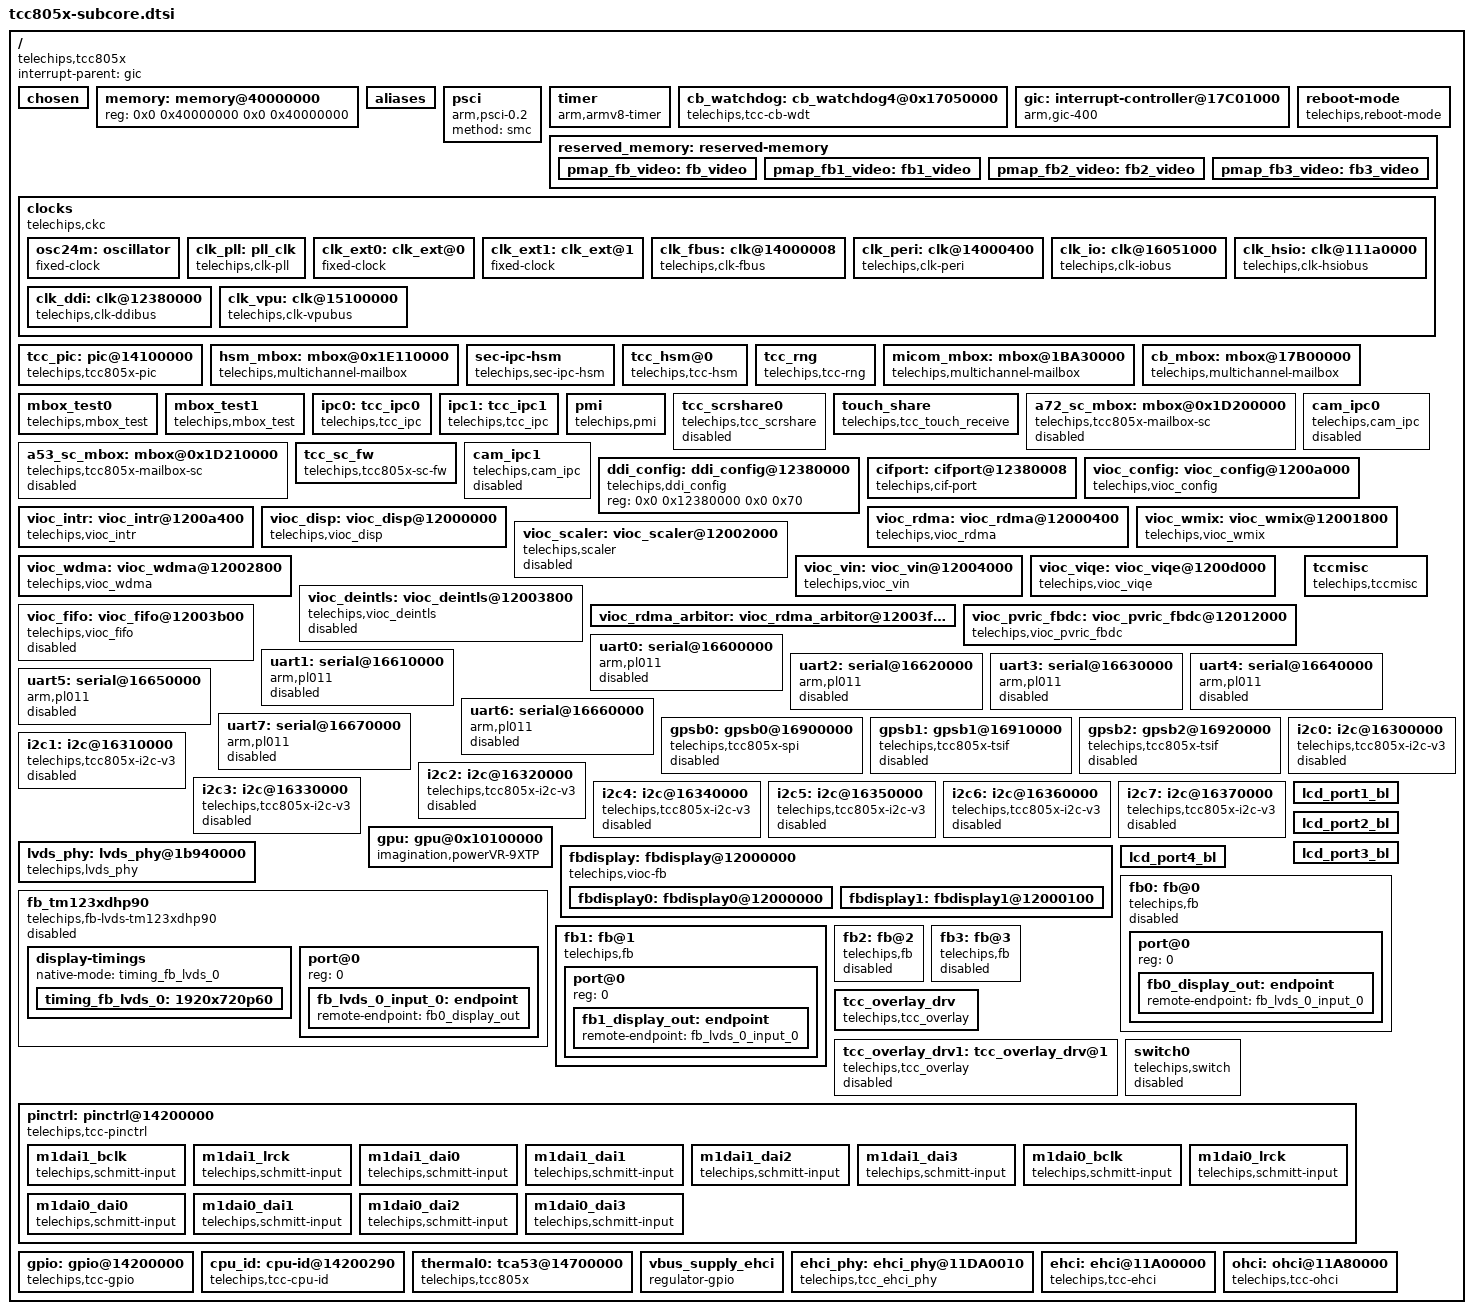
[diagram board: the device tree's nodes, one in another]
// SPDX-License-Identifier: (GPL-2.0-or-later OR MIT)
/*
 * Copyright (C) Telechips Inc.
 */

#include <dt-bindings/interrupt-controller/arm-gic.h>
#include <dt-bindings/clock/telechips,tcc805x-clks.h>
#include <dt-bindings/reset/telechips,tcc805x-reset.h>
#include <dt-bindings/display/tcc805x-vioc.h>
#include <dt-bindings/power/tcc805x,boot-mode.h>
#include <dt-bindings/gpio/gpio.h>
#include <dt-bindings/input/input.h>
#include <dt-bindings/mailbox/tcc805x_multi_mailbox/tcc_mbox_ch.h>
#include <dt-bindings/display/tcc805x-lvds.h>

/ {
	compatible = "telechips,tcc805x";
	interrupt-parent = <&gic>;
	#address-cells = <2>;
	#size-cells = <2>;

	chosen: chosen {
		bootargs = "vmalloc=480M cgroup_disable=memory console=ttyAMA0,115200n8 quiet";
		stdout-path = &uart4;
	};

	memory: memory@40000000 {
		#address-cells = <2>;
		#size-cells = <2>;
		device_type = "memory";
//		reg = <0x0 0x40000000 0x0 0x20000000>;
		reg = <0x0 0x40000000 0x0 0x40000000>;
	};

	aliases: aliases {
		serial0 = &uart0;
		serial1 = &uart1;
		serial2 = &uart2;
		serial3 = &uart3;
		serial4 = &uart4;
		serial5 = &uart5;
		serial6 = &uart6;
		serial7 = &uart7;
		i2c0 = &i2c0;
		i2c1 = &i2c1;
		i2c2 = &i2c2;
		i2c3 = &i2c3;
		i2c4 = &i2c4;
		i2c5 = &i2c5;
		i2c6 = &i2c6;
		i2c7 = &i2c7;
		switch0 = &switch0;
                fb0 = &fb0;
                fb1 = &fb1;
                fb2 = &fb2;
                fb3 = &fb3;
		tcc-overlay-drv1 = &tcc_overlay_drv1;
	};

	psci {
		compatible = "arm,psci-0.2";
		method = "smc";
	};

	timer {
		compatible = "arm,armv8-timer";
		interrupts = <GIC_PPI 13 (GIC_CPU_MASK_SIMPLE(4) | IRQ_TYPE_LEVEL_LOW)>,
			     <GIC_PPI 14 (GIC_CPU_MASK_SIMPLE(4) | IRQ_TYPE_LEVEL_LOW)>,
			     <GIC_PPI 11 (GIC_CPU_MASK_SIMPLE(4) | IRQ_TYPE_LEVEL_LOW)>,
			     <GIC_PPI 10 (GIC_CPU_MASK_SIMPLE(4) | IRQ_TYPE_LEVEL_LOW)>;
	};

	cb_watchdog: cb_watchdog4@0x17050000 {
		compatible = "telechips,tcc-cb-wdt";
		reg = <0x0 0x17050000 0x0 0x10>,
		      <0x0 0x14300010 0x0 0x10>,
		      <0x0 0x14300060 0x0 0x4>;
		interrupts = <GIC_SPI 34 IRQ_TYPE_LEVEL_HIGH>;
		clock-names = "clk_wdt", "clk_kick";
		clocks = <&clk_peri PERI_CB_WDT>, <&clk_peri PERI_TCT>;
		clock-frequency = <24000000>;

		kick-timer-id = /bits/ 8 <0x1>;
		pretimeout-sec = <5>;
		timeout-sec = <20>;
	};

	gic: interrupt-controller@17C01000 {
		compatible = "arm,gic-400";
		#interrupt-cells = <3>;
		#address-cells = <0>;
		interrupt-controller;
		reg = <0x0 0x17C01000 0x0 0x1000>,
		      <0x0 0x17C02000 0x0 0x2000>,
		      <0x0 0x17C04000 0x0 0x2000>,
		      <0x0 0x17C06000 0x0 0x2000>;
	};

	reboot-mode {
		compatible = "telechips,reboot-mode";
		mode-normal = <BOOT_NORMAL>;
		mode-bootloader = <BOOT_FASTBOOT>;
		mode-recovery = <BOOT_RECOVERY>;
		mode-ddrcheck = <BOOT_DDR_CHECK>;
		record-panic = <BOOT_PANIC>;
	};

	reserved_memory: reserved-memory {
		#address-cells = <2>;
		#size-cells = <2>;
		ranges;

		pmap_fb_video: fb_video {};
		pmap_fb1_video: fb1_video {};
		pmap_fb2_video: fb2_video {};
		pmap_fb3_video: fb3_video {};
	};

	clocks {
		compatible = "telechips,ckc";

		osc24m: oscillator {
			compatible = "fixed-clock";
			#clock-cells = <0>;
			clock-frequency = <24000000>;
			clock-output-names = "osc24m";
		};

		clk_pll: pll_clk {
			compatible = "telechips,clk-pll";
			#clock-cells = <1>;
			clocks = <&osc24m>;
			clock-output-names = "pll0", "pll1", "pll2", "pll3",
					     "pll4";
		};

		clk_ext0: clk_ext@0 {
			compatible = "fixed-clock";
			#clock-cells = <0>;
			clock-frequency = <24000000>;
			clock-output-names = "clk_ext0";
		};

		clk_ext1: clk_ext@1 {
			compatible = "fixed-clock";
			#clock-cells = <0>;
			clock-frequency = <24000000>;
			clock-output-names = "clk_ext1";
		};

		clk_fbus: clk@14000008 {
			compatible = "telechips,clk-fbus";
			#clock-cells = <1>;
			clock-indices =
				<FBUS_CPU0>, <FBUS_CPU1>, <FBUS_CBUS>, <FBUS_CMBUS>,
				<FBUS_HSIO>, <FBUS_SMU>, <FBUS_GPU>, <FBUS_DDI>,
				<FBUS_G2D>, <FBUS_IO>, <FBUS_HSM>, <FBUS_PCIe0>,
				<FBUS_PCIe1>, <FBUS_VBUS>, <FBUS_CODA>, <FBUS_CHEVCDEC>,
				<FBUS_BHEVCDEC>, <FBUS_CHEVCENC>, <FBUS_BHEVCENC>, <FBUS_MEM>,
				<FBUS_MEM_SUB>, <FBUS_MEM_PHY_USER>,
				<FBUS_MEM_PHY_PERI>;
			clock-output-names =
				"fbus_cpu0", "fbus_cpu1", "fbus_cbus", "fbus_cmbus",
				"fbus_hsio", "fbus_smu", "fbus_gpu", "fbus_ddi",
				"fbus_g2d", "fbus_io", "fbus_hsm", "fbus_pcie0",
				"fbus_pcie1", "fbus_vbus", "fbus_coda", "fbus_chevcdec",
				"fbus_bhevcdec", "fbus_chevcenc", "fbus_bhevcenc", "fbus_mem",
				"fbus_mem_sub", "fbus_mem_phy_user",
				"fbus_mem_phy_peri";
			telechips,clock-flags =
				<0>,    /* FBUS_CPU0 */
				<CLK_IGNORE_UNUSED>,    /* FBUS_CPU1 */
				<(CLK_SET_RATE_GATE | CLK_IGNORE_UNUSED)>,    /* FBUS_CBUS */
				<(CLK_SET_RATE_GATE | CLK_IGNORE_UNUSED)>,    /* FBUS_CMBUS */
				<(CLK_SET_RATE_GATE | CLK_IGNORE_UNUSED)>,    /* FBUS_HSIO */
				<(CLK_SET_RATE_GATE | CLK_IGNORE_UNUSED)>,    /* FBUS_SMU */
				<(CLK_SET_RATE_GATE | CLK_IGNORE_UNUSED)>,   /* FBUS_GPU */
				<(CLK_SET_RATE_GATE | CLK_IGNORE_UNUSED)>,    /* FBUS_DDI */
				<(CLK_SET_RATE_GATE | CLK_IGNORE_UNUSED)>,    /* FBUS_G2D */
				<(CLK_SET_RATE_GATE | CLK_IS_CRITICAL)>,    /* FBUS_IO */
				<(CLK_SET_RATE_GATE | CLK_IGNORE_UNUSED)>,    /* FBUS_HSM */
				<(CLK_SET_RATE_GATE | CLK_IGNORE_UNUSED)>,    /* FBUS_PCIe0 */
				<(CLK_SET_RATE_GATE | CLK_IGNORE_UNUSED)>,    /* FBUS_PCIe1 */
				<(CLK_SET_RATE_GATE | CLK_IGNORE_UNUSED)>,    /* FBUS_VBUS */
				<(CLK_SET_RATE_GATE | CLK_IGNORE_UNUSED)>,    /* FBUS_CODA */
				<(CLK_SET_RATE_GATE | CLK_IGNORE_UNUSED)>,    /* FBUS_CHEVCDEC */
				<(CLK_SET_RATE_GATE | CLK_IGNORE_UNUSED)>,    /* FBUS_BHEVCDEC */
				<(CLK_SET_RATE_GATE | CLK_IGNORE_UNUSED)>,    /* FBUS_CHEVCENC */
				<(CLK_SET_RATE_GATE | CLK_IGNORE_UNUSED)>,    /* FBUS_BHEVCENC */
				<(CLK_SET_RATE_GATE | CLK_IGNORE_UNUSED)>,    /* FBUS_MEM */
				<(CLK_SET_RATE_GATE | CLK_IGNORE_UNUSED)>,    /* FBUS_MEM_SUB */
				<(CLK_SET_RATE_GATE | CLK_IGNORE_UNUSED)>,    /* FBUS_MEM_PHY_USER */
				<(CLK_SET_RATE_GATE | CLK_IGNORE_UNUSED)>;    /* FBUS_MEM_PHY_PERI */
		};

		clk_peri: clk@14000400 {
			compatible = "telechips,clk-peri";
			#clock-cells = <1>;
			clock-indices =
				<PERI_TCX>, <PERI_TCT>, <PERI_TCZ>,
				<PERI_LCDTIMER>, <PERI_LCD0>, <PERI_LCD1>,
				<PERI_LCD2>, <PERI_CPUINTERFACE0>,
				<PERI_CPUINTERFACE1>, <PERI_LCD3>, <PERI_GMAC>,
				<PERI_GMAC_PTP>, <PERI_PCIE0_AUX>,
				<PERI_PCIE0_REF_EXT>, <PERI_PCIE0_PHY_CR_CLK>,
				<PERI_PCIE1_AUX>, <PERI_PCIE1_REF_EXT>,
				<PERI_PCIE1_PHY_CR_CLK>, <PERI_RMT>, <PERI_GPSB3>,
				<PERI_SDMMC1>, <PERI_SDMMC2>, <PERI_CEC1_CORE>,
				<PERI_MDAI0>, <PERI_MFLT0_DAI>, <PERI_MSPDIF0>,
				<PERI_SRCH0_CORE>, <PERI_SRCH0_FILTER>,
				<PERI_SRCH0_SPDIF>, <PERI_PDM>, <PERI_CEC1_SFR>,
				<PERI_TSADC>, <PERI_I2C0>, <PERI_I2C1>, <PERI_I2C2>,
				<PERI_I2C3>, <PERI_UART0>, <PERI_UART1>,
				<PERI_UART2>, <PERI_UART3>, <PERI_MDAI1>,
				<PERI_MFLT1_DAI>, <PERI_MSPDIF1>, <PERI_MDAI2>,
				<PERI_GPSB0>, <PERI_GPSB1>, <PERI_GPSB2>,
				<PERI_GPSBMS0>, <PERI_GPSBMS1>, <PERI_GPSBMS2>,
				<PERI_UART4>, <PERI_AUX0_INPUT>,
				<PERI_AUX1_INPUT>, <PERI_MFLT2_DAI>,
				<PERI_AUX0_OUTPUT>, <PERI_AUX1_OUTPUT>,
				<PERI_MSPDIF2>, <PERI_IC_TC>, <PERI_SRCH1_CORE>,
				<PERI_SRCH1_FILTER>, <PERI_SRCH1_SPDIF>,
				<PERI_SRCH2_CORE>, <PERI_SRCH2_FILTER>,
				<PERI_SRCH2_SPDIF>, <PERI_SRCH3_CORE>,
				<PERI_SRCH3_FILTER>, <PERI_SRCH3_SPDIF>,
				<PERI_UART5>, <PERI_UART6>, <PERI_UART7>,
				<PERI_UART8>, <PERI_MDAI3>, <PERI_MFLT3_DAI>,
				<PERI_MSPDIF3>, <PERI_TSRX0>, <PERI_TSRX1>,
				<PERI_TSRX2>, <PERI_TSRX3>, <PERI_TSRX4>,
				<PERI_TSRX5>, <PERI_TSRX6>, <PERI_TSRX7>,
				<PERI_TSRX8>, <PERI_CB_WDT>, <PERI_OUT0>,
				<PERI_OUT1>, <PERI_OUT2>, <PERI_OUT3>, <PERI_OUT4>,
				<PERI_OUT5>, <PERI_HSMB>;

				clock-output-names =
				"peri_tcx", "peri_tct", "peri_tcz",
				"peri_lcdtimer", "peri_lcd0", "peri_lcd1",
				"peri_lcd2", "peri_cpuinterface0",
				"peri_cpuinterface1", "peri_lcd3", "peri_gmac",
				"peri_gmac_ptp", "peri_pcie0_aux",
				"peri_pcie0_ref_ext", "peri_pcie0_phy_cr_clk",
				"peri_pcie1_aux", "peri_pcie1_ref_ext",
				"peri_pcie1_phy_cr_clk", "peri_rmt", "peri_gpsb3",
				"peri_sdmmc1", "peri_sdmmc2", "peri_cec1_core",
				"peri_mdai0", "peri_mflt0_dai", "peri_mspdif0",
				"peri_srch0_core", "peri_srch0_filter",
				"peri_srch0_spdif", "peri_pdm", "peri_cec1_sfr",
				"peri_tsadc", "peri_i2c0", "peri_i2c1", "peri_i2c2",
				"peri_i2c3", "peri_uart0", "peri_uart1",
				"peri_uart2", "peri_uart3", "peri_mdai1",
				"peri_mflt1_dai", "peri_mspdif1", "peri_mdai2",
				"peri_gpsb0", "peri_gpsb1", "peri_gpsb2",
				"peri_gpsbms0", "peri_gpsbms1", "peri_gpsbms2",
				"peri_uart4", "peri_aux0_input",
				"peri_aux1_input", "peri_mflt2_dai",
				"peri_aux0_output", "peri_aux1_output",
				"peri_mspdif2", "peri_ic_tc", "peri_srch1_core",
				"peri_srch1_filter", "peri_srch1_spdif",
				"peri_srch2_core", "peri_srch2_filter",
				"peri_srch2_spdif", "peri_srch3_core",
				"peri_srch3_filter", "peri_srch3_spdif",
				"peri_uart5", "peri_uart6", "peri_uart7",
				"peri_uart8", "peri_mdai3", "peri_mflt3_dai",
				"peri_mspdif3", "peri_tsrx0", "peri_tsrx1",
				"peri_tsrx2", "peri_tsrx3", "peri_tsrx4",
				"peri_tsrx5", "peri_tsrx6", "peri_tsrx7",
				"peri_tsrx8", "peri_cb_wdt", "peri_out0",
				"peri_out1", "peri_out2", "peri_out3", "peri_out4",
				"peri_out5", "peri_hsmb";
			telechips,clock-flags =
				<CLK_IGNORE_UNUSED>,    /* PERI_TCX */
				<CLK_IGNORE_UNUSED>,    /* PERI_TCT */
				<CLK_IGNORE_UNUSED>,    /* PERI_TCZ */
				<CLK_IGNORE_UNUSED>,    /* PERI_LCDTIMER */
				<CLK_IGNORE_UNUSED>,    /* PERI_LCD0 */
				<CLK_IGNORE_UNUSED>,    /* PERI_LCD1 */
				<CLK_IGNORE_UNUSED>,    /* PERI_LCD2 */
				<CLK_IGNORE_UNUSED>,    /* PERI_CPUINTERFACE0 */
				<CLK_IGNORE_UNUSED>,    /* PERI_CPUINTERFACE1 */
				<CLK_IGNORE_UNUSED>,    /* PERI_LCD3 */
				<CLK_IGNORE_UNUSED>,    /* PERI_GMAC */
				<CLK_IGNORE_UNUSED>,    /* PERI_GMAC_PTP */
				<CLK_IGNORE_UNUSED>,    /* PERI_PCIE0_AUX */
				<CLK_IGNORE_UNUSED>,    /* PERI_PCIE0_REF_EXT */
				<CLK_IGNORE_UNUSED>,    /* PERI_PCIE0_PHY_CR_CLK */
				<CLK_IGNORE_UNUSED>,    /* PERI_PCIE1_AUX */
				<CLK_IGNORE_UNUSED>,    /* PERI_PCIE1_REF_EXT */
				<CLK_IGNORE_UNUSED>,    /* PERI_PCIE1_PHY_CR_CLK */
				<CLK_IGNORE_UNUSED>,    /* PERI_RMT */
				<CLK_IGNORE_UNUSED>,    /* PERI_GPSB3 */
				<CLK_IGNORE_UNUSED>,    /* PERI_SDMMC1 */
				<CLK_IGNORE_UNUSED>,    /* PERI_SDMMC2 */
				<CLK_IGNORE_UNUSED>,    /* PERI_CEC1_CORE */
				<CLK_IGNORE_UNUSED>,    /* PERI_MDAI0 */
				<CLK_IGNORE_UNUSED>,    /* PERI_MFLT0_DAI */
				<CLK_IGNORE_UNUSED>,    /* PERI_MSPDIF0 */
				<CLK_IGNORE_UNUSED>,    /* PERI_SRCH0_CORE */
				<CLK_IGNORE_UNUSED>,    /* PERI_SRCH0_FILTER */
				<CLK_IGNORE_UNUSED>,    /* PERI_SRCH0_SPDIF */
				<CLK_IGNORE_UNUSED>,    /* PERI_PDM */
				<CLK_IGNORE_UNUSED>,    /* PERI_CEC1_SFR */
				<CLK_IGNORE_UNUSED>,    /* PERI_TSADC */
				<CLK_IGNORE_UNUSED>,    /* PERI_I2C0 */
				<CLK_IGNORE_UNUSED>,    /* PERI_I2C1 */
				<CLK_IGNORE_UNUSED>,    /* PERI_I2C2 */
				<CLK_IGNORE_UNUSED>,    /* PERI_I2C3 */
				<CLK_IGNORE_UNUSED>,    /* PERI_UART0 */
				<CLK_IGNORE_UNUSED>,    /* PERI_UART1 */
				<CLK_IGNORE_UNUSED>,    /* PERI_UART2 */
				<CLK_IGNORE_UNUSED>,    /* PERI_UART3 */
				<CLK_IGNORE_UNUSED>,    /* PERI_MDAI1 */
				<CLK_IGNORE_UNUSED>,    /* PERI_MFLT1_DAI */
				<CLK_IGNORE_UNUSED>,    /* PERI_MSPDIF1 */
				<CLK_IGNORE_UNUSED>,    /* PERI_MDAI2 */
				<CLK_IGNORE_UNUSED>,    /* PERI_GPSB0 */
				<CLK_IGNORE_UNUSED>,    /* PERI_GPSB1 */
				<CLK_IGNORE_UNUSED>,    /* PERI_GPSB2 */
				<CLK_IGNORE_UNUSED>,    /* PERI_GPSBMS0 */
				<CLK_IGNORE_UNUSED>,    /* PERI_GPSBMS1 */
				<CLK_IGNORE_UNUSED>,    /* PERI_GPSBMS2 */
				<CLK_IGNORE_UNUSED>,    /* PERI_UART4 */
				<CLK_IGNORE_UNUSED>,    /* PERI_AUX0_INPUT */
				<CLK_IGNORE_UNUSED>,    /* PERI_AUX1_INPUT */
				<CLK_IGNORE_UNUSED>,    /* PERI_MFLT2_DAI */
				<CLK_IGNORE_UNUSED>,    /* PERI_AUX0_OUTPUT */
				<CLK_IGNORE_UNUSED>,    /* PERI_AUX1_OUTPUT */
				<CLK_IGNORE_UNUSED>,    /* PERI_MSPDIF2 */
				<CLK_IGNORE_UNUSED>,    /* PERI_IC_TC */
				<CLK_IGNORE_UNUSED>,    /* PERI_SRCH1_CORE */
				<CLK_IGNORE_UNUSED>,    /* PERI_SRCH1_FILTER */
				<CLK_IGNORE_UNUSED>,    /* PERI_SRCH1_SPDIF */
				<CLK_IGNORE_UNUSED>,    /* PERI_SRCH2_CORE */
				<CLK_IGNORE_UNUSED>,    /* PERI_SRCH2_FILTER */
				<CLK_IGNORE_UNUSED>,    /* PERI_SRCH2_SPDIF */
				<CLK_IGNORE_UNUSED>,    /* PERI_SRCH3_CORE */
				<CLK_IGNORE_UNUSED>,    /* PERI_SRCH3_FILTER */
				<CLK_IGNORE_UNUSED>,    /* PERI_SRCH3_SPDIF */
				<CLK_IGNORE_UNUSED>,    /* PERI_UART5 */
				<CLK_IGNORE_UNUSED>,    /* PERI_UART6 */
				<CLK_IGNORE_UNUSED>,    /* PERI_UART7 */
				<CLK_IGNORE_UNUSED>,    /* PERI_UART8 */
				<CLK_IGNORE_UNUSED>,    /* PERI_MDAI3 */
				<CLK_IGNORE_UNUSED>,    /* PERI_MFLT3_DAI */
				<CLK_IGNORE_UNUSED>,    /* PERI_MSPDIF3 */
				<CLK_IGNORE_UNUSED>,    /* PERI_TSRX0 */
				<CLK_IGNORE_UNUSED>,    /* PERI_TSRX1 */
				<CLK_IGNORE_UNUSED>,    /* PERI_TSRX2 */
				<CLK_IGNORE_UNUSED>,    /* PERI_TSRX3 */
				<CLK_IGNORE_UNUSED>,    /* PERI_TSRX4 */
				<CLK_IGNORE_UNUSED>,    /* PERI_TSRX5 */
				<CLK_IGNORE_UNUSED>,    /* PERI_TSRX6 */
				<CLK_IGNORE_UNUSED>,    /* PERI_TSRX7 */
				<CLK_IGNORE_UNUSED>,    /* PERI_TSRX8 */
				<CLK_IGNORE_UNUSED>,    /* PERI_CB_WDT */
				<CLK_IGNORE_UNUSED>,    /* PERI_OUT0 */
				<CLK_IGNORE_UNUSED>,    /* PERI_OUT1 */
				<CLK_IGNORE_UNUSED>,    /* PERI_OUT2 */
				<CLK_IGNORE_UNUSED>,    /* PERI_OUT3 */
				<CLK_IGNORE_UNUSED>,    /* PERI_OUT4 */
				<CLK_IGNORE_UNUSED>,    /* PERI_OUT5 */
				<CLK_IGNORE_UNUSED>;    /* PERI_HSMB */
		};

		clk_io: clk@16051000 {
			compatible = "telechips,clk-iobus";
			#clock-cells = <1>;
			clocks = <&clk_fbus FBUS_IO>;
			clock-indices =
				<IOBUS_IC_TC>, <IOBUS_GPSB6>, <IOBUS_PL080>,
                                <IOBUS_ASRC>, <IOBUS_DMA0>, <IOBUS_DMA1>,
                                <IOBUS_DMA2>, <IOBUS_DMA>, <IOBUS_PWM>,
                                <IOBUS_I2C_S2>, <IOBUS_REMOCON>, <IOBUS_PRT>,
                                <IOBUS_ADMA0>, <IOBUS_DAI0>, <IOBUS_SPDIF0>,
                                <IOBUS_AUDIO0>, <IOBUS_ADMA3>, <IOBUS_DAI3>,
                                <IOBUS_SPDIF3>, <IOBUS_AUDIO3>, <IOBUS_I2C_M0>,
                                <IOBUS_I2C_M1>, <IOBUS_I2C_M2>, <IOBUS_I2C_M3>,
                                <IOBUS_I2C_S0>, <IOBUS_I2C_S1>, <IOBUS_I2C0>,
                                <IOBUS_I2C1>, <IOBUS_GPSB_2>, <IOBUS_GPSB0>,
                                <IOBUS_GPSB1>, <IOBUS_GPSB2>, <IOBUS_GPSB3>,
                                <IOBUS_GPSB4>, <IOBUS_GPSB5>, <IOBUS_GPSB>,
                                <IOBUS_I2C_S3>, <IOBUS_I2C_M4>, <IOBUS_I2C_M5>,
                                <IOBUS_I2C_M6>, <IOBUS_I2C_M7>, <IOBUS_UART0>,
                                <IOBUS_UART1>, <IOBUS_UART2>, <IOBUS_UART3>,
                                <IOBUS_UART4>, <IOBUS_UART5>, <IOBUS_UART6>,
                                <IOBUS_UART7>, <IOBUS_UART8>, <IOBUS_SMARTCARD4>,
                                <IOBUS_UDMA0>, <IOBUS_UDMA1>, <IOBUS_UDMA2>,
                                <IOBUS_UDMA3>, <IOBUS_UART_SMARTCARD0>,
                                <IOBUS_UART_SMARTCARD1>, <IOBUS_UDMA4>, <IOBUS_UDMA5>,
                                <IOBUS_UDMA6>, <IOBUS_UDMA7>, <IOBUS_UDMA8>,
                                <IOBUS_ADMA1>, <IOBUS_DAI1>, <IOBUS_SPDIF1>,
                                <IOBUS_AUDIO1>, <IOBUS_ADMA2>, <IOBUS_DAI2>,
                                <IOBUS_SPDIF2>, <IOBUS_AUDIO2>, <IOBUS_ADMA4>,
                                <IOBUS_DAI4>, <IOBUS_SPDIF4>, <IOBUS_AUDIO4>,
                                <IOBUS_ADMA5>, <IOBUS_DAI5>, <IOBUS_SPDIF5>,
                                <IOBUS_AUDIO5>, <IOBUS_ADMA6>, <IOBUS_DAI6>,
                                <IOBUS_SPDIF6>, <IOBUS_AUDIO6>, <IOBUS_ADMA7>,
                                <IOBUS_DAI7>, <IOBUS_AUDIO7>, <IOBUS_GDMA1>,
                                <IOBUS_SDMMC1>, <IOBUS_SDMMC2>, <IOBUS_SDMMC>,
                                <IOBUS_SMC>, <IOBUS_NFC>, <IOBUS_EDICFG>,
                                <IOBUS_EDI>, <IOBUS_RTC>;
			clock-output-names =
				"iobus_ic_tc", "iobus_gpsb6", "iobus_pl080",
                                "iobus_asrc", "iobus_dma0", "iobus_dma1",
                                "iobus_dma2", "iobus_dma", "iobus_pwm",
                                "iobus_i2c_s2", "iobus_remocon", "iobus_prt",
                                "iobus_adma0", "iobus_dai0", "iobus_spdif0",
                                "iobus_audio0", "iobus_adma3", "iobus_dai3",
                                "iobus_spdif3", "iobus_audio3", "iobus_i2c_m0",
                                "iobus_i2c_m1", "iobus_i2c_m2", "iobus_i2c_m3",
                                "iobus_i2c_s0", "iobus_i2c_s1", "iobus_i2c0",
                                "iobus_i2c1", "iobus_gpsb_2", "iobus_gpsb0",
                                "iobus_gpsb1", "iobus_gpsb2", "iobus_gpsb3",
                                "iobus_gpsb4", "iobus_gpsb5", "iobus_gpsb",
                                "iobus_i2c_s3", "iobus_i2c_m4", "iobus_i2c_m5",
                                "iobus_i2c_m6", "iobus_i2c_m7", "iobus_uart0",
                                "iobus_uart1", "iobus_uart2", "iobus_uart3",
                                "iobus_uart4", "iobus_uart5", "iobus_uart6",
                                "iobus_uart7", "iobus_uart8", "iobus_smartcard4",
                                "iobus_udma0", "iobus_udma1", "iobus_udma2",
                                "iobus_udma3", "iobus_uart_smartcard0",
                                "iobus_uart_smartcard1", "iobus_udma4", "iobus_udma5",
                                "iobus_udma6", "iobus_udma7", "iobus_udma8",
                                "iobus_adma1", "iobus_dai1", "iobus_spdif1",
                                "iobus_audio1", "iobus_adma2", "iobus_dai2",
                                "iobus_spdif2", "iobus_audio2", "iobus_adma4",
                                "iobus_dai4", "iobus_spdif4", "iobus_audio4",
                                "iobus_adma5", "iobus_dai5", "iobus_spdif5",
                                "iobus_audio5", "iobus_adma6", "iobus_dai6",
                                "iobus_spdif6", "iobus_audio6", "iobus_adma7",
                                "iobus_dai7", "iobus_audio7", "iobus_gdma1",
                                "iobus_sdmmc1", "iobus_sdmmc2", "iobus_sdmmc",
                                "iobus_smc", "iobus_nfc", "iobus_edicfg",
                                "iobus_edi", "iobus_rtc";
			telechips,clock-flags =
				<CLK_IGNORE_UNUSED>,    /* IOBUS_IC_TC */
                                <CLK_IGNORE_UNUSED>,    /* IOBUS_GPSB6 */
                                <CLK_IGNORE_UNUSED>,    /* IOBUS_PL080 */
                                <CLK_IGNORE_UNUSED>,    /* IOBUS_ASRC */
                                <CLK_IGNORE_UNUSED>,    /* IOBUS_DMA0 */
                                <CLK_IGNORE_UNUSED>,    /* IOBUS_DMA1 */
                                <CLK_IGNORE_UNUSED>,    /* IOBUS_DMA2 */
                                <CLK_IGNORE_UNUSED>,    /* IOBUS_DMA */
                                <CLK_IGNORE_UNUSED>,    /* IOBUS_PWM */
                                <CLK_IGNORE_UNUSED>,    /* IOBUS_I2C_S2 */
                                <CLK_IGNORE_UNUSED>,    /* IOBUS_REMOCON */
                                <CLK_IGNORE_UNUSED>,    /* IOBUS_PRT */
                                <CLK_IGNORE_UNUSED>,    /* IOBUS_ADMA0 */
                                <CLK_IGNORE_UNUSED>,    /* IOBUS_DAI0 */
                                <CLK_IGNORE_UNUSED>,    /* IOBUS_SPDIF0 */
                                <CLK_IGNORE_UNUSED>,    /* IOBUS_AUDIO0 */
                                <CLK_IGNORE_UNUSED>,    /* IOBUS_ADMA3 */
                                <CLK_IGNORE_UNUSED>,    /* IOBUS_DAI3 */
                                <CLK_IGNORE_UNUSED>,    /* IOBUS_SPDIF3 */
                                <CLK_IGNORE_UNUSED>,    /* IOBUS_AUDIO3 */
                                <CLK_IGNORE_UNUSED>,    /* IOBUS_I2C_M0 */
                                <CLK_IGNORE_UNUSED>,    /* IOBUS_I2C_M1 */
                                <CLK_IGNORE_UNUSED>,    /* IOBUS_I2C_M2 */
                                <CLK_IGNORE_UNUSED>,    /* IOBUS_I2C_M3 */
                                <CLK_IGNORE_UNUSED>,    /* IOBUS_I2C_S0 */
                                <CLK_IGNORE_UNUSED>,    /* IOBUS_I2C_S1 */
                                <CLK_IGNORE_UNUSED>,    /* IOBUS_I2C0 */
                                <CLK_IGNORE_UNUSED>,    /* IOBUS_I2C1 */
                                <CLK_IGNORE_UNUSED>,    /* IOBUS_GPSB_2 */
                                <CLK_IGNORE_UNUSED>,    /* IOBUS_GPSB0 */
                                <CLK_IGNORE_UNUSED>,    /* IOBUS_GPSB1 */
                                <CLK_IGNORE_UNUSED>,    /* IOBUS_GPSB2 */
                                <CLK_IGNORE_UNUSED>,    /* IOBUS_GPSB3 */
                                <CLK_IGNORE_UNUSED>,    /* IOBUS_GPSB4 */
                                <CLK_IGNORE_UNUSED>,    /* IOBUS_GPSB5 */
                                <CLK_IGNORE_UNUSED>,    /* IOBUS_GPSB */
                                <CLK_IGNORE_UNUSED>,    /* IOBUS_I2C_S3 */
                                <CLK_IGNORE_UNUSED>,    /* IOBUS_I2C_M4 */
                                <CLK_IGNORE_UNUSED>,    /* IOBUS_I2C_M5 */
                                <CLK_IGNORE_UNUSED>,    /* IOBUS_I2C_M6 */
                                <CLK_IGNORE_UNUSED>,    /* IOBUS_I2C_M7 */
                                <CLK_IGNORE_UNUSED>,    /* IOBUS_UART0 */
                                <CLK_IGNORE_UNUSED>,    /* IOBUS_UART1 */
                                <CLK_IGNORE_UNUSED>,    /* IOBUS_UART2 */
                                <CLK_IGNORE_UNUSED>,    /* IOBUS_UART3 */
                                <CLK_IGNORE_UNUSED>,    /* IOBUS_UART4 */
                                <CLK_IGNORE_UNUSED>,    /* IOBUS_UART5 */
                                <CLK_IGNORE_UNUSED>,    /* IOBUS_UART6 */
                                <CLK_IGNORE_UNUSED>,    /* IOBUS_UART7 */
                                <CLK_IGNORE_UNUSED>,    /* IOBUS_UART8 */
                                <CLK_IGNORE_UNUSED>,    /* IOBUS_SMARTCARD4 */
                                <CLK_IGNORE_UNUSED>,    /* IOBUS_UDMA0 */
                                <CLK_IGNORE_UNUSED>,    /* IOBUS_UDMA1 */
                                <CLK_IGNORE_UNUSED>,    /* IOBUS_UDMA2 */
                                <CLK_IGNORE_UNUSED>,    /* IOBUS_UDMA3 */
                                <CLK_IGNORE_UNUSED>,    /* IOBUS_UART_SMARTCARD0 */
                                <CLK_IGNORE_UNUSED>,    /* IOBUS_UART_SMARTCARD1 */
                                <CLK_IGNORE_UNUSED>,    /* IOBUS_UDMA4 */
                                <CLK_IGNORE_UNUSED>,    /* IOBUS_UDMA5 */
				<CLK_IGNORE_UNUSED>,    /* IOBUS_UDMA6 */
                                <CLK_IGNORE_UNUSED>,    /* IOBUS_UDMA7 */
                                <CLK_IGNORE_UNUSED>,    /* IOBUS_UDMA8 */
                                <CLK_IGNORE_UNUSED>,    /* IOBUS_ADMA1 */
                                <CLK_IGNORE_UNUSED>,    /* IOBUS_DAI1 */
                                <CLK_IGNORE_UNUSED>,    /* IOBUS_SPDIF1 */
                                <CLK_IGNORE_UNUSED>,    /* IOBUS_AUDIO1 */
                                <CLK_IGNORE_UNUSED>,    /* IOBUS_ADMA2 */
                                <CLK_IGNORE_UNUSED>,    /* IOBUS_DAI2 */
                                <CLK_IGNORE_UNUSED>,    /* IOBUS_SPDIF2 */
                                <CLK_IGNORE_UNUSED>,    /* IOBUS_AUDIO2 */
                                <CLK_IGNORE_UNUSED>,    /* IOBUS_ADMA4 */
                                <CLK_IGNORE_UNUSED>,    /* IOBUS_DAI4 */
                                <CLK_IGNORE_UNUSED>,    /* IOBUS_SPDIF4 */
                                <CLK_IGNORE_UNUSED>,    /* IOBUS_AUDIO4 */
                                <CLK_IGNORE_UNUSED>,    /* IOBUS_ADMA5 */
                                <CLK_IGNORE_UNUSED>,    /* IOBUS_DAI5 */
                                <CLK_IGNORE_UNUSED>,    /* IOBUS_SPDIF5 */
                                <CLK_IGNORE_UNUSED>,    /* IOBUS_AUDIO5 */
                                <CLK_IGNORE_UNUSED>,    /* IOBUS_ADMA6 */
                                <CLK_IGNORE_UNUSED>,    /* IOBUS_DAI6 */
                                <CLK_IGNORE_UNUSED>,    /* IOBUS_SPDIF6 */
                                <CLK_IGNORE_UNUSED>,    /* IOBUS_AUDIO6 */
                                <CLK_IGNORE_UNUSED>,    /* IOBUS_ADMA7 */
                                <CLK_IGNORE_UNUSED>,    /* IOBUS_DAI7 */
                                <CLK_IGNORE_UNUSED>,    /* IOBUS_AUDIO7 */
                                <CLK_IGNORE_UNUSED>,    /* IOBUS_GDMA1 */
                                <CLK_IGNORE_UNUSED>,    /* IOBUS_SDMMC1 */
                                <CLK_IGNORE_UNUSED>,    /* IOBUS_SDMMC2 */
                                <CLK_IGNORE_UNUSED>,    /* IOBUS_SDMMC */
                                <CLK_IGNORE_UNUSED>,    /* IOBUS_SMC */
                                <CLK_IGNORE_UNUSED>,    /* IOBUS_NFC */
                                <CLK_IGNORE_UNUSED>,    /* IOBUS_EDICFG */
                                <CLK_IGNORE_UNUSED>,    /* IOBUS_EDI */
                                <CLK_IGNORE_UNUSED>;    /* IOBUS_RTC */
		};

		clk_hsio: clk@111a0000 {
			compatible = "telechips,clk-hsiobus";
			#clock-cells = <1>;
			clocks = <&clk_fbus FBUS_HSIO>;
			clock-indices =
				<HSIOBUS_USB30>, <HSIOBUS_GMAC>,
                                <HSIOBUS_USB20H>, <HSIOBUS_CIPHER>,
                                <HSIOBUS_DWC_OTG>, <HSIOBUS_SECURE_WRAP>,
                                <HSIOBUS_TRNG>;
			clock-output-names =
				"hsiobus_usb30", "hsiobus_gmac",
                                "hsiobus_usb20h", "hsiobus_cipher",
                                "hsiobus_dwc_otg", "hsiobus_secure_wrap",
                                "hsiobus_trng";
			telechips,clock-flags =
				<CLK_IGNORE_UNUSED>,    /* HSIOBUS_USB30 */
                                <CLK_IGNORE_UNUSED>,    /* HSIOBUS_GMAC */
                                <CLK_IGNORE_UNUSED>,    /* HSIOBUS_USB20H */
                                <CLK_IGNORE_UNUSED>,    /* HSIOBUS_CIPHER */
                                <CLK_IGNORE_UNUSED>,    /* HSIOBUS_DWC_OTG */
                                <CLK_IGNORE_UNUSED>,    /* HSIOBUS_SECURE_WRAP */
                                <CLK_IGNORE_UNUSED>;    /* HSIOBUS_TRNG */
		};

		clk_ddi: clk@12380000 {
			compatible = "telechips,clk-ddibus";
			#clock-cells = <1>;
			clocks = <&clk_fbus FBUS_DDI>;
			clock-indices =
				<DDIBUS_VIOC>, <DDIBUS_HDMI>, <DDIBUS_MIPI>,
				<DDIBUS_LVDS>;
			clock-output-names =
				"ddibus_vioc", "ddibus_hdmi", "ddibus_mipi",
				"ddibus_lvds";
			telechips,clock-flags =
				<CLK_IGNORE_UNUSED>,	/* DDIBUS_VIOC */
				<CLK_IGNORE_UNUSED>,	/* DDIBUS_HDMI */
				<CLK_IGNORE_UNUSED>,	/* DDIBUS_MIPI */
				<CLK_IGNORE_UNUSED>;	/* DDIBUS_LVDS */
		};

		clk_vpu: clk@15100000 {
			compatible = "telechips,clk-vpubus";
			#clock-cells = <1>;
			clocks = <&clk_fbus FBUS_VBUS>;
			clock-indices =
				<VIDEOBUS_JPEG>, <VIDEOBUS_CODA_BUS>,
				<VIDEOBUS_CODA_CORE>, <VIDEOBUS_HEVC_BUS>,
				<VIDEOBUS_HEVC_CORE>, <VIDEOBUS_HEVC_ENCODER>;
			clock-output-names =
				"videobus_jpeg", "videobus_coda_bus",
				"videobus_coda_core", "videobus_hevc_bus",
				"videobus_hevc_core", "videobus_hevc_encoder";
			telechips,clock-flags =
				<CLK_IGNORE_UNUSED>,	/* VIDEOBUS_JPEG */
				<CLK_IGNORE_UNUSED>,	/* VIDEOBUS_CODA_BUS */
				<CLK_IGNORE_UNUSED>,	/* VIDEOBUS_CODA_CORE */
				<CLK_IGNORE_UNUSED>,	/* VIDEOBUS_HEVC_BUS */
				<CLK_IGNORE_UNUSED>,	/* VIDEOBUS_HEVC_CORE */
				<CLK_IGNORE_UNUSED>;	/* VIDEOBUS_HEVC_ENCODER */
		};
	};

	tcc_pic: pic@14100000 {
		compatible = "telechips,tcc805x-pic";
		reg = <0x0 0x141000E0 0x0 0x0018>,  /* pol_0_base */
		      <0x0 0x14600100 0x0 0x0024>,  /* pol_1_base */
		      <0x0 0x14800040 0x0 0x003C>,  /* cmb_cm4_base */
		      <0x0 0x14900040 0x0 0x003C>,  /* strgb_cm4_base */
		      <0x0 0x0 0x0 0x0>;            /* ca7_irqo_en_base */
		demarcation = <192>;
		max_irq = <480>;
	};

	/* A53 <-> HSM core */
	hsm_mbox: mbox@0x1E110000 {
		compatible = "telechips,multichannel-mailbox";
		reg = <0x0 0x1E110000 0x0 0x100>;
		interrupts = <GIC_SPI 308 IRQ_TYPE_LEVEL_HIGH>,
					<GIC_SPI 336 IRQ_TYPE_LEVEL_HIGH>;
		#mbox-cells = <1>;
		max-channel = <TCC_HSM_MBOX0_MAX>;
	};

	sec-ipc-hsm {
		compatible = "telechips,sec-ipc-hsm";
		mbox-names = "sec-ipc-hsm";
		mboxes = <&hsm_mbox TCC_HSM_MBOX1>;
		mbox-id = TCC_MBOX_HSM_ID;
	};

	tcc_hsm@0 {
		compatible = "telechips,tcc-hsm";
		status = "okay";
	};

	tcc_rng {
		compatible = "telechips,tcc-rng";
		status = "okay";
	};

	/* A53 <-> R5 */
	micom_mbox: mbox@1BA30000 {
		compatible = "telechips,multichannel-mailbox";
		reg = <0x0 0x1BA30000 0x0 0x100>;
		interrupts = <GIC_SPI 444 IRQ_TYPE_LEVEL_HIGH>,
			<GIC_SPI 445 IRQ_TYPE_LEVEL_HIGH>;
		#mbox-cells = <1>;
		max-channel = <TCC_MICOM_MBOX1_MAX>;
	};

	/* A53 <-> A72 */
	cb_mbox: mbox@17B00000 {
		compatible = "telechips,multichannel-mailbox";
		reg = <0x0 0x17B00000 0x0 0x100>;
		interrupts = <GIC_SPI 365 IRQ_TYPE_LEVEL_HIGH>,
			<GIC_SPI 366 IRQ_TYPE_LEVEL_HIGH>;
		#mbox-cells = <1>;
		max-channel = <TCC_CB_MBOX_MAX>;
	};

	/* micom_mbox test */
	mbox_test0: mbox_test0 {
		compatible = "telechips,mbox_test";
		device-name = "micom_mbox_test";
		mbox-names ="mbox_test";
		mboxes = <&micom_mbox TCC_MICOM_MBOX1_TEST>;
		mbox-id = TCC_MBOX_TEST_ID;
	};

	/* cb_mbox test */
	mbox_test1: mbox_test1 {
	    compatible = "telechips,mbox_test";
	    device-name = "cb_mbox_test";
	    mbox-names ="mbox_test";
	    mboxes = <&cb_mbox TCC_CB_MBOX_TEST>;
	    mbox-id = TCC_MBOX_TEST_ID;
	};

	/* ipc for r5(micom) */
	ipc0: tcc_ipc0 {
		compatible = "telechips,tcc_ipc";
		device-name = "tcc_ipc_micom";
		mbox-names ="micom-ipc";
		mboxes = <&micom_mbox TCC_MICOM_MBOX1_IPC>;
		mbox-id = TCC_MBOX_IPC_ID;
	  };

	/* ipc for A72 */
	ipc1: tcc_ipc1 {
		compatible = "telechips,tcc_ipc";
		device-name = "tcc_ipc_ap";
		mbox-names ="ap-ipc";
		mboxes = <&cb_mbox TCC_CB_MBOX_IPC>;
		mbox-id = TCC_MBOX_IPC_ID;
	};

	/* power management interface driver */
	pmi {
		compatible = "telechips,pmi";
		mboxes = <&micom_mbox TCC_MICOM_MBOX1_POWER>;
		mbox-id = TCC_MBOX_POWER_ID;
	};

	/* tcc_scrshare for Sub */
	tcc_scrshare0: tcc_scrshare0 {
		compatible = "telechips,tcc_scrshare";
		device-name ="tcc_scrshare_sub";
		mbox-names ="sub-scrshare";
		mboxes = <&cb_mbox TCC_CB_MBOX_SCRSHARE>;
		mbox-id = TCC_MBOX_SCRSHARE_ID;
		overlay_driver_names = "/dev/overlay1";
		status = "disabled";
    };

	/* touch receive driver */
	touch_share {
	    compatible = "telechips,tcc_touch_receive";
	    mbox-names ="tr-mbox";
	    mboxes = <&cb_mbox TCC_CB_MBOX_TCHSHARE>;
	    mbox-id = TCC_MBOX_TCHSHARE_ID;
	    xmax = <1920>;
	    ymax = <720>;
	};

	/* A72 <-> SC */
	a72_sc_mbox: mbox@0x1D200000 {
		status = "disabled";
		compatible = "telechips,tcc805x-mailbox-sc";
		reg = <0x0 0x1D200000 0x0 0x80>;
		interrupts = <GIC_SPI 319 IRQ_TYPE_LEVEL_HIGH>,
		             <GIC_SPI 329 IRQ_TYPE_LEVEL_HIGH>;
		#mbox-cells = <1>;
	};

	/* A53 <-> SC */
	a53_sc_mbox: mbox@0x1D210000 {
		status = "disabled";
		compatible = "telechips,tcc805x-mailbox-sc";
		reg = <0x0 0x1D210000 0x0 0x80>;
		interrupts = <GIC_SPI 320 IRQ_TYPE_LEVEL_HIGH>,
		             <GIC_SPI 330 IRQ_TYPE_LEVEL_HIGH>;
		#mbox-cells = <1>;
	};

	tcc_sc_fw: tcc_sc_fw {
		status = "disabled";
		compatible = "telechips,tcc805x-sc-fw";
	};

	/* cam_ipc for A53 */
	cam_ipc0: cam_ipc0 {
		compatible = "telechips,cam_ipc";
		device-name ="cam_ipc_ap";
		mbox-names ="cam-ipc-ap";
		mboxes = <&cb_mbox TCC_CB_MBOX_CAMIPC>;
		mbox-id = TCC_MBOX_CAMIPC_ID;
		status = "disabled";
	};

	/* cam_ipc for trvc */
	cam_ipc1: cam_ipc1 {
		compatible = "telechips,cam_ipc";
		device-name ="cam_ipc_micom";
		mbox-names ="cam-ipc-micom";
		mboxes = <&micom_mbox TCC_MICOM_MBOX1_CAMIPC>;
		mbox-id = TCC_MBOX_CAMIPC_ID;
		status = "disabled";
	};

	/*
	 * Display Bus Block
	 */
	ddi_config: ddi_config@12380000 {
		compatible = "telechips,ddi_config";
		reg = <0x0 0x12380000 0x0 0x70>;
	};

	cifport: cifport@12380008 {
		compatible = "telechips,cif-port";
		reg = <0x0 0x12380008 0x0 0x4>;
		statue = "okay";
	};

	vioc_config: vioc_config@1200a000 {
		compatible = "telechips,vioc_config";
		reg =  <0x0 0x1200a000 0x0 0x1000>,
			/* VIOC_REMAP */
		       <0x0 0x12046000 0x0 0x1000>;
	};

	vioc_intr: vioc_intr@1200a400 {
		compatible = "telechips,vioc_intr";
		reg =  <0x0 0x1200a400 0x0 0x100>,
			/* VIOC_REMAP */
		       <0x0 0x12046400 0x0 0x100>;
		interrupts = <GIC_SPI VIOC0_IRQI IRQ_TYPE_LEVEL_HIGH>;
	};

	vioc_disp: vioc_disp@12000000 {
		compatible = "telechips,vioc_disp";
		reg =  <0x0 0x12000000 0x0 0x100
			0x0 0x12000100 0x0 0x100
			0x0 0x12000200 0x0 0x100
			0x0 0x12000300 0x0 0x100>,
			/* VIOC_REMAP */
		       <0x0 0x12000000 0x0 0x100
			0x0 0x12001000 0x0 0x100
			0x0 0x12002000 0x0 0x100
			0x0 0x12003000 0x0 0x100>;
		interrupts = <GIC_SPI VIOC0_IRQI IRQ_TYPE_LEVEL_HIGH>, <GIC_SPI VIOC0_IRQI IRQ_TYPE_LEVEL_HIGH>, <GIC_SPI VIOC0_IRQI IRQ_TYPE_LEVEL_HIGH>, <GIC_SPI VIOC0_IRQI IRQ_TYPE_LEVEL_HIGH>;
		clocks = <&clk_ddi DDIBUS_VIOC>, <&clk_peri PERI_LCD0>, <&clk_peri PERI_LCD1>, <&clk_peri PERI_LCD2>, <&clk_peri PERI_LCD3>;
		clock-names = "ddi-clk", "disp0-clk", "disp1-clk", "disp2-clk", "disp3-clk";
	};

	vioc_rdma: vioc_rdma@12000400 {
		compatible = "telechips,vioc_rdma";
		reg =  <0x0 0x12000400 0x0 0x100
			0x0 0x12000500 0x0 0x100
			0x0 0x12000600 0x0 0x100
			0x0 0x12000700 0x0 0x100
			0x0 0x12000800 0x0 0x100
			0x0 0x12000900 0x0 0x100
			0x0 0x12000a00 0x0 0x100
			0x0 0x12000b00 0x0 0x100
			0x0 0x12000c00 0x0 0x100
			0x0 0x12000d00 0x0 0x100
			0x0 0x12000e00 0x0 0x100
			0x0 0x12000f00 0x0 0x100
			0x0 0x12001000 0x0 0x100
			0x0 0x12001100 0x0 0x100
			0x0 0x12001200 0x0 0x100
			0x0 0x12001300 0x0 0x100
			0x0 0x12001400 0x0 0x100
			0x0 0x12001500 0x0 0x100>,
			/* VIOC_REMAP */
		       <0x0 0x12004000 0x0 0x100
			0x0 0x12005000 0x0 0x100
			0x0 0x12006000 0x0 0x100
			0x0 0x12007000 0x0 0x100
			0x0 0x12008000 0x0 0x100
			0x0 0x12009000 0x0 0x100
			0x0 0x1200a000 0x0 0x100
			0x0 0x1200b000 0x0 0x100
			0x0 0x1200c000 0x0 0x100
			0x0 0x1200d000 0x0 0x100
			0x0 0x1200e000 0x0 0x100
			0x0 0x1200f000 0x0 0x100
			0x0 0x12010000 0x0 0x100
			0x0 0x12011000 0x0 0x100
			0x0 0x12012000 0x0 0x100
			0x0 0x12013000 0x0 0x100
			0x0 0x12014000 0x0 0x100
			0x0 0x12015000 0x0 0x100>;
		interrupts = <GIC_SPI VIOC0_IRQI IRQ_TYPE_LEVEL_HIGH>,
			     <GIC_SPI VIOC0_IRQI IRQ_TYPE_LEVEL_HIGH>,
			     <GIC_SPI VIOC0_IRQI IRQ_TYPE_LEVEL_HIGH>,
			     <GIC_SPI VIOC0_IRQI IRQ_TYPE_LEVEL_HIGH>,
			     <GIC_SPI VIOC0_IRQI IRQ_TYPE_LEVEL_HIGH>,
			     <GIC_SPI VIOC0_IRQI IRQ_TYPE_LEVEL_HIGH>,
			     <GIC_SPI VIOC0_IRQI IRQ_TYPE_LEVEL_HIGH>,
			     <GIC_SPI VIOC0_IRQI IRQ_TYPE_LEVEL_HIGH>,
			     <GIC_SPI VIOC0_IRQI IRQ_TYPE_LEVEL_HIGH>,
			     <GIC_SPI VIOC0_IRQI IRQ_TYPE_LEVEL_HIGH>,
			     <GIC_SPI VIOC0_IRQI IRQ_TYPE_LEVEL_HIGH>,
			     <GIC_SPI VIOC0_IRQI IRQ_TYPE_LEVEL_HIGH>,
			     <GIC_SPI VIOC0_IRQI IRQ_TYPE_LEVEL_HIGH>,
			     <GIC_SPI VIOC0_IRQI IRQ_TYPE_LEVEL_HIGH>,
			     <GIC_SPI VIOC0_IRQI IRQ_TYPE_LEVEL_HIGH>,
			     <GIC_SPI VIOC0_IRQI IRQ_TYPE_LEVEL_HIGH>,
			     <GIC_SPI VIOC0_IRQI IRQ_TYPE_LEVEL_HIGH>,
			     <GIC_SPI VIOC0_IRQI IRQ_TYPE_LEVEL_HIGH>;
	};

	vioc_wmix: vioc_wmix@12001800 {
		compatible = "telechips,vioc_wmix";
		reg =  <0x0 0x12001800 0x0 0x100
			0x0 0x12001900 0x0 0x100
			0x0 0x12001a00 0x0 0x100
			0x0 0x12001b00 0x0 0x100
			0x0 0x12001c00 0x0 0x100
			0x0 0x12001d00 0x0 0x100
			0x0 0x12001e00 0x0 0x100>,
			/* VIOC_REMAP */
		       <0x0 0x12018000 0x0 0x100
			0x0 0x12019000 0x0 0x100
			0x0 0x1201a000 0x0 0x100
			0x0 0x1201b000 0x0 0x100
			0x0 0x1201c000 0x0 0x100
			0x0 0x1201d000 0x0 0x100
			0x0 0x1201e000 0x0 0x100>;
		interrupts = <GIC_SPI VIOC0_IRQI IRQ_TYPE_LEVEL_HIGH>,
			     <GIC_SPI VIOC0_IRQI IRQ_TYPE_LEVEL_HIGH>,
			     <GIC_SPI VIOC0_IRQI IRQ_TYPE_LEVEL_HIGH>,
			     <GIC_SPI VIOC0_IRQI IRQ_TYPE_LEVEL_HIGH>,
			     <GIC_SPI VIOC0_IRQI IRQ_TYPE_LEVEL_HIGH>,
			     <GIC_SPI VIOC0_IRQI IRQ_TYPE_LEVEL_HIGH>,
			     <GIC_SPI VIOC0_IRQI IRQ_TYPE_LEVEL_HIGH>;
	};

	vioc_scaler: vioc_scaler@12002000 {
		compatible = "telechips,scaler";
		reg =  <0x0 0x12002000 0x0 0x100
			0x0 0x12002100 0x0 0x100
			0x0 0x12002200 0x0 0x100
			0x0 0x12002300 0x0 0x100
			0x0 0x12002400 0x0 0x100
			0x0 0x12002500 0x0 0x100
			0x0 0x12002600 0x0 0x100
			0x0 0x12002700 0x0 0x100>,
			/* VIOC_REMAP */
		       <0x0 0x12020000 0x0 0x100
			0x0 0x12021000 0x0 0x100
			0x0 0x12022000 0x0 0x100
			0x0 0x12023000 0x0 0x100
			0x0 0x12024000 0x0 0x100
			0x0 0x12025000 0x0 0x100
			0x0 0x12026000 0x0 0x100
			0x0 0x12027000 0x0 0x100>;
		status = "disabled";
	};

	vioc_wdma: vioc_wdma@12002800 {
		compatible = "telechips,vioc_wdma";
		reg =  <0x0 0x12002800 0x0 0x100 0x0 0x12002900 0x0 0x100
			0x0 0x12002a00 0x0 0x100 0x0 0x12002b00 0x0 0x100
			0x0 0x12002c00 0x0 0x100 0x0 0x12002d00 0x0 0x100
			0x0 0x12002e00 0x0 0x100 0x0 0x12002f00 0x0 0x100
			0x0 0x12003000 0x0 0x100 0x0 0x12014000 0x0 0x100
			0x0 0x12014100 0x0 0x100 0x0 0x12014200 0x0 0x100
			0x0 0x12014300 0x0 0x100 0x0 0x12014400 0x0 0x100>,
			/* VIOC_REMAP */
		       <0x0 0x12028000 0x0 0x100 0x0 0x12029000 0x0 0x100
			0x0 0x1202a000 0x0 0x100 0x0 0x1202b000 0x0 0x100
			0x0 0x1202c000 0x0 0x100 0x0 0x1202d000 0x0 0x100
			0x0 0x1202e000 0x0 0x100 0x0 0x1202f000 0x0 0x100
			0x0 0x12030000 0x0 0x100 0x0 0x12052000 0x0 0x100
			0x0 0x12053000 0x0 0x100 0x0 0x12054000 0x0 0x100
			0x0 0x12059000 0x0 0x100 0x0 0x1205a000 0x0 0x100>;
		interrupts = <GIC_SPI VIOC0_IRQI IRQ_TYPE_LEVEL_HIGH>,
			     <GIC_SPI VIOC0_IRQI IRQ_TYPE_LEVEL_HIGH>,
			     <GIC_SPI VIOC0_IRQI IRQ_TYPE_LEVEL_HIGH>,
			     <GIC_SPI VIOC0_IRQI IRQ_TYPE_LEVEL_HIGH>,
			     <GIC_SPI VIOC0_IRQI IRQ_TYPE_LEVEL_HIGH>,
			     <GIC_SPI VIOC0_IRQI IRQ_TYPE_LEVEL_HIGH>,
			     <GIC_SPI VIOC0_IRQI IRQ_TYPE_LEVEL_HIGH>,
			     <GIC_SPI VIOC0_IRQI IRQ_TYPE_LEVEL_HIGH>,
			     <GIC_SPI VIOC0_IRQI IRQ_TYPE_LEVEL_HIGH>,
			     <GIC_SPI VIOC0_IRQI IRQ_TYPE_LEVEL_HIGH>,
			     <GIC_SPI VIOC0_IRQI IRQ_TYPE_LEVEL_HIGH>,
			     <GIC_SPI VIOC0_IRQI IRQ_TYPE_LEVEL_HIGH>,
			     <GIC_SPI VIOC0_IRQI IRQ_TYPE_LEVEL_HIGH>,
			     <GIC_SPI VIOC0_IRQI IRQ_TYPE_LEVEL_HIGH>;
	};

	vioc_vin: vioc_vin@12004000 {
		compatible = "telechips,vioc_vin";
		reg =     <0x0 0x12004000 0x0 0x400 0x0 0x12004400 0x0 0x600
			   0x0 0x12005000 0x0 0x400 0x0 0x12005400 0x0 0x600
			   0x0 0x12006000 0x0 0x400 0x0 0x12006400 0x0 0x600
			   0x0 0x12007000 0x0 0x400 0x0 0x12007400 0x0 0x600
			   0x0 0x12018000 0x0 0x400 0x0 0x12018400 0x0 0x600
			   0x0 0x12019000 0x0 0x400 0x0 0x12019400 0x0 0x600
			   0x0 0x1201a000 0x0 0x400 0x0 0x1201a400 0x0 0x600
			   0x0 0x1201b000 0x0 0x400 0x0 0x1201b400 0x0 0x600>,
			/* VIOC_REMAP */
			  <0x0 0x12040000 0x0 0x400 0x0 0x12040400 0x0 0x600
			   0x0 0x12041000 0x0 0x400 0x0 0x12041400 0x0 0x600
			   0x0 0x12042000 0x0 0x400 0x0 0x12042400 0x0 0x600
			   0x0 0x12043000 0x0 0x400 0x0 0x12043400 0x0 0x600
			   0x0 0x12055000 0x0 0x400 0x0 0x12055400 0x0 0x600
			   0x0 0x12056000 0x0 0x400 0x0 0x12056400 0x0 0x600
			   0x0 0x12057000 0x0 0x400 0x0 0x12057400 0x0 0x600
			   0x0 0x12058000 0x0 0x400 0x0 0x12058400 0x0 0x600>;
		interrupts = <GIC_SPI VIOC0_IRQI IRQ_TYPE_LEVEL_HIGH>,
			     <GIC_SPI VIOC0_IRQI IRQ_TYPE_LEVEL_HIGH>,
			     <GIC_SPI VIOC0_IRQI IRQ_TYPE_LEVEL_HIGH>,
			     <GIC_SPI VIOC0_IRQI IRQ_TYPE_LEVEL_HIGH>,
			     <GIC_SPI VIOC0_IRQI IRQ_TYPE_LEVEL_HIGH>,
			     <GIC_SPI VIOC0_IRQI IRQ_TYPE_LEVEL_HIGH>,
			     <GIC_SPI VIOC0_IRQI IRQ_TYPE_LEVEL_HIGH>,
			     <GIC_SPI VIOC0_IRQI IRQ_TYPE_LEVEL_HIGH>,
			     <GIC_SPI VIOC0_IRQI IRQ_TYPE_LEVEL_HIGH>,
			     <GIC_SPI VIOC0_IRQI IRQ_TYPE_LEVEL_HIGH>,
			     <GIC_SPI VIOC0_IRQI IRQ_TYPE_LEVEL_HIGH>,
			     <GIC_SPI VIOC0_IRQI IRQ_TYPE_LEVEL_HIGH>,
			     <GIC_SPI VIOC0_IRQI IRQ_TYPE_LEVEL_HIGH>,
			     <GIC_SPI VIOC0_IRQI IRQ_TYPE_LEVEL_HIGH>,
			     <GIC_SPI VIOC0_IRQI IRQ_TYPE_LEVEL_HIGH>,
			     <GIC_SPI VIOC0_IRQI IRQ_TYPE_LEVEL_HIGH>;
	};

	vioc_viqe: vioc_viqe@1200d000 {
		compatible = "telechips,vioc_viqe";
		reg =  <0x0 0x1200d000 0x0 0x1000
			0x0 0x12010000 0x0 0x1000>,
			/* VIOC_REMAP */
		       <0x0 0x1204b000 0x0 0x1000
			0x0 0x1204e000 0x0 0x1000>;
	};

	vioc_deintls:vioc_deintls@12003800 {
		compatible = "telechips,vioc_deintls";
		reg =  <0x0 0x12003800 0x0 0x100>,
			/* VIOC_REMAP */
		       <0x0 0x12038000 0x0 0x100>;
		status = "disabled";
	};

	vioc_fifo:vioc_fifo@12003b00 {
		compatible = "telechips,vioc_fifo";
		reg =  <0x0 0x12003b00 0x0 0x100>,
			/* VIOC_REMAP */
		       <0x0 0x1203b000 0x0 0x100>;
		status = "disabled";
	};

	vioc_rdma_arbitor:vioc_rdma_arbitor@12003f00 {
		reg =  <0x0 0x12003f00 0x0 0x20
			0x0 0x12003f20 0x0 0x20
			0x0 0x12003f40 0x0 0x20
			0x0 0x12003f60 0x0 0x20>,
			/* VIOC_REMAP */
		       <0x0 0x1203f000 0x0 0x20
			0x0 0x1203f020 0x0 0x20
			0x0 0x1203f040 0x0 0x20
			0x0 0x1203f060 0x0 0x20>;
		arbitor_num = <4>;
	};

	vioc_pvric_fbdc:vioc_pvric_fbdc@12012000{
		compatible = "telechips,vioc_pvric_fbdc";
		status = "okay";
		reg =  <0x0 0x12012000 0x0 0x100
			0x0 0x12013000 0x0 0x100>,
			/* VIOC_REMAP */
		       <0x0 0x12050000 0x0 0x100
			0x0 0x12051000 0x0 0x100>;
	};

	tccmisc:tccmisc {
		/* Only use kernel-5.4 or up */
		compatible = "telechips,tccmisc";
		status = "okay";
	};

	uart0: serial@16600000 {
		compatible = "arm,pl011", "arm,primecell";
		reg = <0x0 0x16600000 0x0 0x1000>;
		config-reg = <0x16689000 0x8 9>;
		arm,primecell-periphid = <0x001feff7>;
                sc-firmware = <&tcc_sc_fw>;
		interrupts = <GIC_SPI 88 IRQ_TYPE_LEVEL_HIGH>;
		clocks = <&clk_peri PERI_UART0>, <&clk_io IOBUS_UART0>;
		clock-names = "uartclk", "apb_pclk";
		assigned-clocks = <&clk_peri PERI_UART0>;
		assigned-clock-rates = <48000000>;
		pinctrl-names = "default";
		status = "disabled";
	};

	uart1: serial@16610000 {
		compatible = "arm,pl011", "arm,primecell";
		reg = <0x0 0x16610000 0x0 0x1000>;
		config-reg = <0x16689000 0x8 9>;
		arm,primecell-periphid = <0x001feff7>;
		sc-firmware = <&tcc_sc_fw>;
		interrupts = <GIC_SPI 89 IRQ_TYPE_LEVEL_HIGH>;
		clocks = <&clk_peri PERI_UART1>, <&clk_io IOBUS_UART1>;
		clock-names = "uartclk", "apb_pclk";
		assigned-clocks = <&clk_peri PERI_UART1>;
		assigned-clock-rates = <48000000>;
		pinctrl-names = "default";
		status = "disabled";
	};

	uart2: serial@16620000 {
		compatible = "arm,pl011", "arm,primecell";
		reg = <0x0 0x16620000 0x0 0x1000>;
		config-reg = <0x16689000 0x8 9>;
		arm,primecell-periphid = <0x001feff7>;
		sc-firmware = <&tcc_sc_fw>;
		interrupts = <GIC_SPI 90 IRQ_TYPE_LEVEL_HIGH>;
		clocks = <&clk_peri PERI_UART2>, <&clk_io IOBUS_UART2>;
		clock-names = "uartclk", "apb_pclk";
		assigned-clocks = <&clk_peri PERI_UART2>;
		assigned-clock-rates = <48000000>;
		pinctrl-names = "default";
		status = "disabled";
	};

	uart3: serial@16630000 {
		compatible = "arm,pl011", "arm,primecell";
		reg = <0x0 0x16630000 0x0 0x1000>;
		config-reg = <0x16689000 0x8 9>;
		arm,primecell-periphid = <0x001feff7>;
		sc-firmware = <&tcc_sc_fw>;
		interrupts = <GIC_SPI 91 IRQ_TYPE_LEVEL_HIGH>;
		clocks = <&clk_peri PERI_UART3>, <&clk_io IOBUS_UART3>;
		clock-names = "uartclk", "apb_pclk";
		assigned-clocks = <&clk_peri PERI_UART3>;
		assigned-clock-rates = <48000000>;
		pinctrl-names = "default";
		status = "disabled";
	};

	uart4: serial@16640000 {
		compatible = "arm,pl011", "arm,primecell";
		reg = <0x0 0x16640000 0x0 0x1000>;
		config-reg = <0x16689000 0x8 9>;
		arm,primecell-periphid = <0x001feff7>;
		sc-firmware = <&tcc_sc_fw>;
		interrupts = <GIC_SPI 69 IRQ_TYPE_LEVEL_HIGH>;
		clocks = <&clk_peri PERI_UART4>, <&clk_io IOBUS_UART4>;
		clock-names = "uartclk", "apb_pclk";
		pinctrl-names = "default";
		status = "disabled";
	};

	uart5: serial@16650000 {
		compatible = "arm,pl011", "arm,primecell";
		reg = <0x0 0x16650000 0x0 0x1000>;
		config-reg = <0x16689000 0x8 9>;
		arm,primecell-periphid = <0x001feff7>;
		sc-firmware = <&tcc_sc_fw>;
		interrupts = <GIC_SPI 111 IRQ_TYPE_LEVEL_HIGH>;
		clocks = <&clk_peri PERI_UART5>, <&clk_io IOBUS_UART5>;
		clock-names = "uartclk", "apb_pclk";
		assigned-clocks = <&clk_peri PERI_UART5>;
		assigned-clock-rates = <48000000>;
		pinctrl-names = "default";
		status = "disabled";
	};

	uart6: serial@16660000 {
		compatible = "arm,pl011", "arm,primecell";
		reg = <0x0 0x16660000 0x0 0x1000>;
		config-reg = <0x16689000 0x8 9>;
		arm,primecell-periphid = <0x001feff7>;
		sc-firmware = <&tcc_sc_fw>;
		interrupts = <GIC_SPI 112 IRQ_TYPE_LEVEL_HIGH>;
		clocks = <&clk_peri PERI_UART6>, <&clk_io IOBUS_UART6>;
		clock-names = "uartclk", "apb_pclk";
		assigned-clocks = <&clk_peri PERI_UART6>;
		assigned-clock-rates = <48000000>;
		pinctrl-names = "default";
		status = "disabled";
	};

	uart7: serial@16670000 {
		compatible = "arm,pl011", "arm,primecell";
		reg = <0x0 0x16670000 0x0 0x1000>;
		config-reg = <0x16689000 0x8 9>;
		arm,primecell-periphid = <0x001feff7>;
		sc-firmware = <&tcc_sc_fw>;
		interrupts = <GIC_SPI 113 IRQ_TYPE_LEVEL_HIGH>;
		clocks = <&clk_peri PERI_UART7>, <&clk_io IOBUS_UART7>;
		clock-names = "uartclk", "apb_pclk";
		assigned-clocks = <&clk_peri PERI_UART7>;
		assigned-clock-rates = <48000000>;
		pinctrl-names = "default";
		status = "disabled";
	};

	gpsb0: gpsb0@16900000 {
		compatible = "telechips,tcc805x-spi";
		reg = <0x0 0x16900000 0x0 0x38>, /* base address */
		      <0x0 0x16960000 0x0 0x20>, /* Port Configuration register */
		      <0x0 0x16980000 0x0 0x20>; /* GPSB_0_AC */
		interrupts = <GIC_SPI 55 IRQ_TYPE_LEVEL_HIGH>;
		clocks = <&clk_peri PERI_GPSB0 &clk_io IOBUS_GPSB0>;
		gpsb-id = <0>;
		status = "disabled";
	};

	gpsb1: gpsb1@16910000 {
		compatible = "telechips,tcc805x-tsif";
		reg = <0x0 0x16910000 0x0 0x38>, /* base address */
		      <0x0 0x16960000 0x0 0x20>, /* Port Configuration register */
		      <0x0 0x16970000 0x0 0x84>, /* PID register */
		      <0x0 0x16980020 0x0 0x20>; /* GPSB_1_AC */
		interrupts = <GIC_SPI 56 IRQ_TYPE_LEVEL_HIGH>;
		clocks = <&clk_peri PERI_GPSB1 &clk_io IOBUS_GPSB1>;
		gpsb-id = <0>;
		status = "disabled";
	};

	gpsb2: gpsb2@16920000 {
		compatible = "telechips,tcc805x-tsif";
		reg = <0x0 0x16920000 0x0 0x38>, /* base address */
		      <0x0 0x16960000 0x0 0x20>, /* Port Configuration register */
		      <0x0 0x16970000 0x0 0x84>, /* PID register */
		      <0x0 0x16980040 0x0 0x20>; /* GPSB_2_AC */
		interrupts = <GIC_SPI 57 IRQ_TYPE_LEVEL_HIGH>;
		clocks = <&clk_peri PERI_GPSB2 &clk_io IOBUS_GPSB2>;
		gpsb-id = <1>;
		status = "disabled";
	};

	i2c0: i2c@16300000 {
		compatible = "telechips,tcc805x-i2c-v3";
		reg = <0x0 0x16300000 0x0 0x28>,
		      <0x0 0x163c0000 0x0 0x14>,
		      <0x0 0x16340000 0x0 0x04>;
		interrupts = <GIC_SPI 61 IRQ_TYPE_LEVEL_HIGH>;
		#address-cells = <1>;
		#size-cells = <0>;
		clocks = <&clk_peri PERI_I2C0 &clk_io IOBUS_I2C_M0 &clk_fbus FBUS_IO>;
		clock-frequency = <400000>;
		port-mux = <0xFF>;	/* default value */
		status = "disabled";
	};

	i2c1: i2c@16310000 {
		compatible = "telechips,tcc805x-i2c-v3";
		reg = <0x0 0x16310000 0x0 0x28>,
		      <0x0 0x163c0000 0x0 0x14>,
		      <0x0 0x16350000 0x0 0x04>;
		interrupts = <GIC_SPI 62 IRQ_TYPE_LEVEL_HIGH>;
		#address-cells = <1>;
		#size-cells = <0>;
		clocks = <&clk_peri PERI_I2C1 &clk_io IOBUS_I2C_M1 &clk_fbus FBUS_IO>;
		clock-frequency = <400000>;
		port-mux = <0xFF>;	/* default value */
		status = "disabled";
	};

	i2c2: i2c@16320000 {
		compatible = "telechips,tcc805x-i2c-v3";
		reg = <0x0 0x16320000 0x0 0x28>,
		      <0x0 0x163c0000 0x0 0x14>,
		      <0x0 0x16360000 0x0 0x04>;
		interrupts = <GIC_SPI 63 IRQ_TYPE_LEVEL_HIGH>;
		#address-cells = <1>;
		#size-cells = <0>;
		clocks = <&clk_peri PERI_I2C2 &clk_io IOBUS_I2C_M2 &clk_fbus FBUS_IO>;
		clock-frequency = <400000>;
		port-mux = <0xFF>;	/* default value */
		status = "disabled";
	};

	i2c3: i2c@16330000 {
		compatible = "telechips,tcc805x-i2c-v3";
		reg = <0x0 0x16330000 0x0 0x28>,
		      <0x0 0x163c0000 0x0 0x14>,
		      <0x0 0x16370000 0x0 0x100>;
		interrupts = <GIC_SPI 64 IRQ_TYPE_LEVEL_HIGH>;
		#address-cells = <1>;
		#size-cells = <0>;
		clocks = <&clk_peri PERI_I2C3 &clk_io IOBUS_I2C_M3 &clk_fbus FBUS_IO>;
		clock-frequency = <400000>;
		port-mux = <0xFF>;	/* default value */
		status = "disabled";
	};

	i2c4: i2c@16340000 {
		compatible = "telechips,tcc805x-i2c-v3";
		reg = <0x0 0x16340000 0x0 0x28>,
		      <0x0 0x163c0000 0x0 0x14>,
		      <0x0 0x16300000 0x0 0x04>;
		interrupts = <GIC_SPI 61 IRQ_TYPE_LEVEL_HIGH>;
		#address-cells = <1>;
		#size-cells = <0>;
		clocks = <&clk_peri PERI_I2C0 &clk_io IOBUS_I2C_M4 &clk_fbus FBUS_IO>;
		clock-frequency = <400000>;
		port-mux = <0xFF>;	/* default value */
		status = "disabled";
	};

	i2c5: i2c@16350000 {
		compatible = "telechips,tcc805x-i2c-v3";
		reg = <0x0 0x16350000 0x0 0x28>,
		      <0x0 0x163c0000 0x0 0x14>,
		      <0x0 0x16310000 0x0 0x04>;
		interrupts = <GIC_SPI 62 IRQ_TYPE_LEVEL_HIGH>;
		#address-cells = <1>;
		#size-cells = <0>;
		clocks = <&clk_peri PERI_I2C1 &clk_io IOBUS_I2C_M5 &clk_fbus FBUS_IO>;
		clock-frequency = <400000>;
		port-mux = <0xFF>;	/* default value */
		status = "disabled";
	};

	i2c6: i2c@16360000 {
		compatible = "telechips,tcc805x-i2c-v3";
		reg = <0x0 0x16360000 0x0 0x28>,
		      <0x0 0x163c0000 0x0 0x14>,
		      <0x0 0x16320000 0x0 0x04>;
		interrupts = <GIC_SPI 63 IRQ_TYPE_LEVEL_HIGH>;
		#address-cells = <1>;
		#size-cells = <0>;
		clocks = <&clk_peri PERI_I2C2 &clk_io IOBUS_I2C_M6 &clk_fbus FBUS_IO>;
		clock-frequency = <400000>;
		port-mux = <0xFF>;	/* default value */
		status = "disabled";
	};

	i2c7: i2c@16370000 {
		compatible = "telechips,tcc805x-i2c-v3";
		reg = <0x0 0x16370000 0x0 0x100>,
		      <0x0 0x163c0000 0x0 0x14>,
		      <0x0 0x16330000 0x0 0x04>;
		interrupts = <GIC_SPI 64 IRQ_TYPE_LEVEL_HIGH>;
		#address-cells = <1>;
		#size-cells = <0>;
		clocks = <&clk_peri PERI_I2C3 &clk_io IOBUS_I2C_M7 &clk_fbus FBUS_IO>;
		clock-frequency = <400000>;
		port-mux = <0xFF>;	/* default value */
		status = "disabled";
	};

	/*
	 * Graphic Bus Block
	 */
	gpu:gpu@0x10100000 {
		compatible = "imagination,powerVR-9XTP";
		status = "okay";
		reg = <0x0 0x10100000 0x0 0x10000>,	/* 3D Graphic Engine Configuration and Control */
		      <0x0 0x10010000 0x0 0x30>;	/* 3D BUS Configuration and Control */
		interrupts = <GIC_SPI 123 IRQ_TYPE_LEVEL_HIGH>,	/* HostOS */
			     <GIC_SPI 124 IRQ_TYPE_LEVEL_HIGH>;	/* GuestOS */
		interrupt-names = "GPU";
		clocks = <&clk_fbus FBUS_GPU>;
		clock-names = "9XTP_clk";
	};

	fbdisplay: fbdisplay@12000000 {
		compatible = "telechips,vioc-fb";
		reg = <0x0 0x12000000 0x0 0x10000>;
		telechips,fbdisplay_num = <0>;
		telechips,rdma_arbitor=<&vioc_rdma_arbitor>;
		memory-region = <&pmap_fb_video &pmap_fb1_video>;

		fbdisplay0:fbdisplay0@12000000{
			telechips,disp = <&vioc_disp VIOC_DISP0>;
			telechips,wmixer = <&vioc_wmix VIOC_WMIX0>;
			telechips,rdma = <&vioc_rdma VIOC_RDMA00 VIOC_RDMA01 VIOC_RDMA02 VIOC_RDMA03>;
			telechips,wdma = <&vioc_wdma VIOC_WDMA00>;
		};

		fbdisplay1:fbdisplay1@12000100{
			telechips,disp = <&vioc_disp VIOC_DISP1>;
			telechips,wmixer = <&vioc_wmix VIOC_WMIX1>;
			telechips,rdma = <&vioc_rdma VIOC_RDMA04 VIOC_RDMA05 VIOC_RDMA06 VIOC_RDMA07>;
			telechips,wdma = <&vioc_wdma VIOC_WDMA01>;
		};
	};

        lvds_phy:lvds_phy@1b940000 {
                 compatible = "telechips,lvds_phy";
                 reg = <0x0 0x1b941000 0x0 0x400>,
                     <0x0 0x1b941000 0x0 0x400>,
                     <0x0 0x1b942800 0x0 0x400>,
                     <0x0 0x1b942c00 0x0 0x400>,
                     <0x0 0x1b940000 0x0 0x400>;
         };

        lcd_port1_bl: lcd_port1_bl {};

        lcd_port2_bl: lcd_port2_bl {};

        lcd_port3_bl: lcd_port3_bl {};

        lcd_port4_bl: lcd_port4_bl {};

	/* Panel for Framebuffer driver */
        fb_tm123xdhp90:fb_tm123xdhp90 {
                #address-cells = <1>;
                #size-cells = <0>;
                compatible = "telechips,fb-lvds-tm123xdhp90";
                status = "disabled";
                lvds0 = <&lvds_phy>;

                mode = <LVDS_DUAL>;   /* 0: single 1: dual */
                phy-ports = <PHY_PORT_D0 PHY_PORT_D1>; /*port main, port sub*/
                lcdc-mux-select = <2>;
                data-mapping = "vesa-24";
                lane-main =
                        <DATA3_LANE CLK_LANE DATA2_LANE DATA1_LANE DATA0_LANE>;
                lane-sub =
                        <DATA0_LANE DATA1_LANE DATA2_LANE CLK_LANE DATA3_LANE>;
                vcm = <1200>;
                vsw = <500>;

                display-timings {
                        native-mode = <&timing_fb_lvds_0>;
                        timing_fb_lvds_0: 1920x720p60 {
                                clock-frequency = <88200000>;
                                hactive = <1920>;
                                vactive = <720>;
                                hfront-porch = <28>;
                                hback-porch = <28>;
                                hsync-len = <8>;
                                hsync-active = <0>;
                                vback-porch = <10>;
                                vfront-porch = <10>;
                                vsync-len = <2>;
                                vsync-active = <0>;
                                de-active = <1>;
                                pixelclk-active = <1>;
                        };
                };
                port@0 {
                        reg = <0>;
                        fb_lvds_0_input_0: endpoint {
                                remote-endpoint = <&fb0_display_out>;
                        };
                };
        };

        fb0: fb@0 { //Cluster
                #address-cells = <1>;
                #size-cells = <0>;
                compatible = "telechips,fb";
                //status = "okay";
                status = "disabled";
                memory-region = <&pmap_fb_video>;
                xres = <1920>;
                yres = <720>;
                bpp = <32>;
				chroma-key = <0x0 0x0 0x0>;
				chroma-mkey = <0xF8 0xFC 0xF8>;
                mode = <FBX_TRIPLE>;
                update-type = <FBX_OVERLAY_UPDATE>;
                device-priority = <FBX_DEVICE_LVDS>;
                telechips,disp = <&vioc_disp VIOC_DISP2>;
                telechips,wmixer = <&vioc_wmix VIOC_WMIX2>;
                telechips,rdma = <&vioc_rdma VIOC_RDMA08>;
                telechips,fbdc = <&vioc_pvric_fbdc VIOC_FBCDEC1>;
                port@0 {
                        reg = <0>;
                        fb0_display_out: endpoint {
                                remote-endpoint = <&fb_lvds_0_input_0>;
                        };
                };
        };

        fb1: fb@1 { //SVM
                compatible = "telechips,fb";
                //status = "disabled";
                status = "okay";
                memory-region = <&pmap_fb1_video>;
                xres = <1920>;
                yres = <1080>;
                bpp = <32>;
				chroma-key = <0x0 0x0 0x0>;
				chroma-mkey = <0xF8 0xFC 0xF8>;
                mode = <FBX_TRIPLE>;
                update-type = <FBX_OVERLAY_UPDATE>;
                device-priority = <FBX_DEVICE_LVDS>;
                telechips,disp = <&vioc_disp VIOC_DISP0>;
                telechips,wmixer = <&vioc_wmix VIOC_WMIX0>;
                telechips,rdma = <&vioc_rdma VIOC_RDMA02>;
                port@0 {
                        reg = <0>;
                        fb1_display_out: endpoint {
                                remote-endpoint = <&fb_lvds_0_input_0>;
                        };
                };
        };

        fb2: fb@2 { //BVM
                compatible = "telechips,fb";
                status = "disabled";
                memory-region = <&pmap_fb2_video>;
                xres = <1920>;
                yres = <720>;
                bpp = <32>;
				chroma-key = <0x0 0x0 0x0>;
				chroma-mkey = <0xF8 0xFC 0xF8>;
                mode = <FBX_TRIPLE>;
                update-type = <FBX_OVERLAY_UPDATE>;
                device-priority = <FBX_DEVICE_LVDS>;
                telechips,disp = <&vioc_disp VIOC_DISP2>;
                telechips,wmixer = <&vioc_wmix VIOC_WMIX2>;
                telechips,rdma = <&vioc_rdma VIOC_RDMA09>;
        };

        fb3: fb@3 { //DPGL
                compatible = "telechips,fb";
                status = "disabled";
                memory-region = <&pmap_fb3_video>;
                xres = <1920>;
                yres = <720>;
                bpp = <32>;
				chroma-key = <0x0 0x0 0x0>;
				chroma-mkey = <0xF8 0xFC 0xF8>;
                mode = <FBX_TRIPLE>;
                update-type = <FBX_NOWAIT_UPDATE>;
                device-priority = <FBX_DEVICE_NONE>;
                no-kernel-logo =<1>;
                telechips,wdma = <&vioc_wdma VIOC_WDMA05>;
                telechips,wmixer = <&vioc_wmix VIOC_WMIX5>;
                telechips,rdma = <&vioc_rdma VIOC_RDMA16>;
        };

	tcc_overlay_drv {
		compatible = "telechips,tcc_overlay";
		display_num = <0>;
		rdmas = <&vioc_rdma VIOC_RDMA00 VIOC_RDMA01 VIOC_RDMA02 VIOC_RDMA03 VIOC_RDMA04 VIOC_RDMA05 VIOC_RDMA06 VIOC_RDMA07>;
		wmixs = <&vioc_wmix VIOC_WMIX0 VIOC_WMIX1>;
		rdma_init_layer = <1>;
		status = "okay";
	};

	tcc_overlay_drv1: tcc_overlay_drv@1 {
		compatible = "telechips,tcc_overlay";
		display_num = <1>;
		rdmas = <&vioc_rdma VIOC_RDMA00 VIOC_RDMA01 VIOC_RDMA02 VIOC_RDMA03 VIOC_RDMA04 VIOC_RDMA05 VIOC_RDMA06 VIOC_RDMA07>;
		wmixs = <&vioc_wmix VIOC_WMIX0 VIOC_WMIX1>;
		rdma_init_layer = <2>;
		status = "disabled";
	};

	switch0:switch0 {
		compatible = "telechips,switch";
		status = "disabled";
	};

	pinctrl: pinctrl@14200000 {
		compatible = "telechips,tcc-pinctrl";
		reg = <0x0 0x14200000 0x0 0x7C0>,
		      <0x0 0x1B937000 0x0 0xA30>;	/* gpio, pmgpio */
		sc-firmware = <&tcc_sc_fw>;
	};

	gpio: gpio@14200000 {
		compatible = "telechips,tcc-gpio";
		reg = <0x0 0x14200000 0x0 0x7C0>;
		sc-firmware = <&tcc_sc_fw>;
	};

	cpu_id: cpu-id@14200290{
		compatible = "telechips,tcc-cpu-id";
		reg = <0x0 0x14200290 0x0 0x4>,
		      <0x0 0x14200298 0x0 0x4>,
		      <0x0 0x1420029C 0x0 0x4>,
		      <0x0 0x14400014 0x0 0x4>;
		status = "okay";
	};

	thermal0: tca53@14700000 {
		compatible = "telechips,tcc805x";

		init = "false";
		sc-firmware = <&tcc_sc_fw>;
		reg = <0x0 0x14700000 0x0 0x160>; //0:Enable register
		status = "okay";

		interrupts = <GIC_SPI 40 IRQ_TYPE_LEVEL_HIGH>;
		cal_type = "TYPE_TWO_POINT_TRIMMING";
		core = <0>;

		threshold_high_temp = <75>;
		threshold_low_temp = <(-40)>;
		interval_time = <262143>;
		#thermal-sensor-cells = <1>;
	};

	vbus_supply_ehci: vbus_supply_ehci {
		compatible = "regulator-gpio";
		regulator-name = "vbus_supply_ehci";
		regulator-type = "voltage";
		regulator-min-microvolt = <0000001>;
		regulator-max-microvolt = <5000000>;
		gpios-states = <0x0>;
		states = <0000001 0x0 5000000 0x1>;
		status = "okay";
	};

	ehci_phy: ehci_phy@11DA0010 {
		compatible = "telechips,tcc_ehci_phy";
		reg = <0x0 0x11DA0010 0x0 0x30>;
		interrupts = <GIC_SPI 143 IRQ_TYPE_LEVEL_HIGH>;
		vbus-supply = <&vbus_supply_ehci>;
		vbus-ctrl-able;
		status = "okay";
	};

	ehci: ehci@11A00000 {
		compatible = "telechips,tcc-ehci";
		reg = <0x0 0x11A00000 0x0 0x108>,
			<0x0 0x11DA0010 0x0 0x54>;
		interrupts = <GIC_SPI 142 IRQ_TYPE_LEVEL_HIGH>;
		telechips,ehci_phy = <&ehci_phy>;
		status = "okay";
	};

	ohci: ohci@11A80000 {
		compatible = "telechips,tcc-ohci";
		reg = <0x0 0x11A80000 0x0 0x60>,
			<0x0 0x11DA0010 0x0 0x54>;
		interrupts = <GIC_SPI 142 IRQ_TYPE_LEVEL_HIGH>;
		status = "okay";
	};
};


&tcc_sc_fw {
	status = "okay";
};

//This is for SDR solution.
&pinctrl {
	m1dai1_bclk: m1dai1_bclk {
		 telechips,schmitt-input;
	};
	m1dai1_lrck: m1dai1_lrck {
		 telechips,schmitt-input;
	};
	m1dai1_dai0: m1dai1_dai0 {
		 telechips,schmitt-input;
	};
	m1dai1_dai1: m1dai1_dai1 {
		 telechips,schmitt-input;
	};
	m1dai1_dai2: m1dai1_dai2 {
		 telechips,schmitt-input;
	};
	m1dai1_dai3: m1dai1_dai3 {
		 telechips,schmitt-input;
	};
	m1dai0_bclk: m1dai0_bclk {
		 telechips,schmitt-input;
	};
	m1dai0_lrck: m1dai0_lrck {
		 telechips,schmitt-input;
	};
	m1dai0_dai0: m1dai0_dai0 {
		 telechips,schmitt-input;
	};
	m1dai0_dai1: m1dai0_dai1 {
		 telechips,schmitt-input;
	};
	m1dai0_dai2: m1dai0_dai2 {
		 telechips,schmitt-input;
	};
	m1dai0_dai3: m1dai0_dai3 {
		 telechips,schmitt-input;
	};
};
